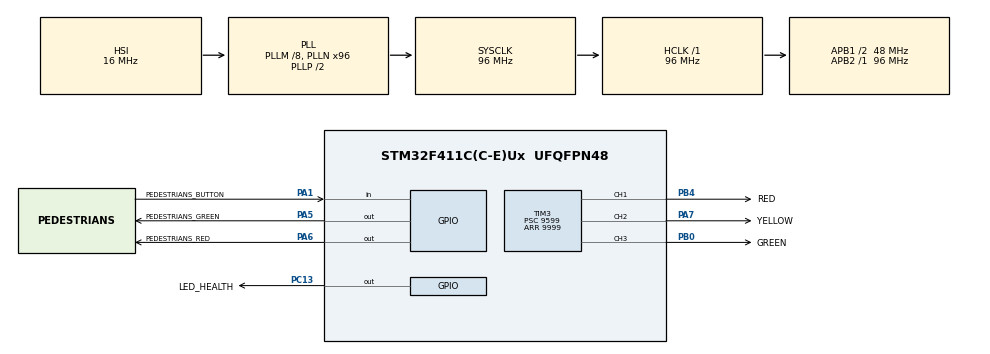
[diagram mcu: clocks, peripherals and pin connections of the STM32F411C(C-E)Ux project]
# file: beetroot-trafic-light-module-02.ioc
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Mcu.Family=STM32F4
Mcu.Name=STM32F411C(C-E)Ux
Mcu.Package=UFQFPN48
NVIC.PriorityGroup=NVIC_PRIORITYGROUP_4
NVIC.TIM2_IRQn=true\:0\:0\:false\:false\:true\:true\:true\:true
PA1.GPIO_Label=PEDESTRIANS_BUTTON
PA1.GPIO_PuPd=GPIO_PULLUP
PA1.Signal=GPIO_Input
PA5.GPIO_Label=PEDESTRIANS_GREEN
PA5.Signal=GPIO_Output
PA6.GPIO_Label=PEDESTRIANS_RED
PA6.Signal=GPIO_Output
PA7.GPIO_Label=YELLOW
PA7.Signal=S_TIM3_CH2
PB0.GPIO_Label=GREEN
PB0.Signal=S_TIM3_CH3
PB4.GPIO_Label=RED
PB4.Signal=S_TIM3_CH1
PC13-ANTI_TAMP.GPIO_Label=LED_HEALTH
PC13-ANTI_TAMP.PinState=GPIO_PIN_SET
PC13-ANTI_TAMP.Signal=GPIO_Output
PH0\ -\ OSC_IN.Mode=HSE-External-Oscillator
PH0\ -\ OSC_IN.Signal=RCC_OSC_IN
PH1\ -\ OSC_OUT.Mode=HSE-External-Oscillator
PH1\ -\ OSC_OUT.Signal=RCC_OSC_OUT
ProjectManager.HeapSize=0x200
ProjectManager.StackSize=0x400
ProjectManager.TargetToolchain=CMake
RCC.48MHZClocksFreq_Value=48000000
RCC.AHBFreq_Value=96000000
RCC.APB1CLKDivider=RCC_HCLK_DIV2
RCC.APB1Freq_Value=48000000
RCC.APB1TimFreq_Value=96000000
RCC.APB2Freq_Value=96000000
RCC.APB2TimFreq_Value=96000000
RCC.CortexFreq_Value=96000000
RCC.HCLKFreq_Value=96000000
RCC.HSE_VALUE=25000000
RCC.HSI_VALUE=16000000
RCC.PLLM=8
RCC.PLLN=96
RCC.SYSCLKFreq_VALUE=96000000
RCC.SYSCLKSource=RCC_SYSCLKSOURCE_PLLCLK
RCC.VCOOutputFreq_Value=192000000
SH.S_TIM3_CH1.0=TIM3_CH1,PWM Generation1 CH1
SH.S_TIM3_CH2.0=TIM3_CH2,PWM Generation2 CH2
SH.S_TIM3_CH3.0=TIM3_CH3,PWM Generation3 CH3
TIM2.Period=349999
TIM2.Prescaler=9599
TIM3.Channel-PWM\ Generation1\ CH1=TIM_CHANNEL_1
TIM3.Channel-PWM\ Generation2\ CH2=TIM_CHANNEL_2
TIM3.Channel-PWM\ Generation3\ CH3=TIM_CHANNEL_3
TIM3.OC1Preload_PWM=DISABLE
TIM3.OC2Preload_PWM=DISABLE
TIM3.OC3Preload_PWM=DISABLE
TIM3.Period=9999
TIM3.Prescaler=9599
VP_TIM2_VS_ClockSourceINT.Mode=Internal
board=custom

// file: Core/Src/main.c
/* USER CODE BEGIN Header */
/**
  ******************************************************************************
  * @file           : main.c
  * @brief          : Main program body
  ******************************************************************************
  * @attention
  *
  * Copyright (c) 2026 STMicroelectronics.
  * All rights reserved.
  *
  * This software is licensed under terms that can be found in the LICENSE file
  * in the root directory of this software component.
  * If no LICENSE file comes with this software, it is provided AS-IS.
  *
  ******************************************************************************
  */
/* USER CODE END Header */
#include "main.h"

/* USER CODE BEGIN Includes */
#include "traffic_light_app.h"
#include "components/health_check.h"
/* USER CODE END Includes */

TIM_HandleTypeDef htim2;
TIM_HandleTypeDef htim3;

void SystemClock_Config(void);
static void MX_GPIO_Init(void);
static void MX_TIM2_Init(void);
static void MX_TIM3_Init(void);

int main(void)
{

  /* MCU Configuration--------------------------------------------------------*/

  /* Reset of all peripherals, Initializes the Flash interface and the Systick. */
  HAL_Init();

  /* Configure the system clock */
  SystemClock_Config();

  /* Initialize all configured peripherals */
  MX_GPIO_Init();
  MX_TIM2_Init();
  MX_TIM3_Init();
  /* USER CODE BEGIN 2 */
  trafic_light_app_start(&htim2, &htim3);
  /* USER CODE END 2 */

  /* Infinite loop */
  while (1)
  {

    /* USER CODE BEGIN 3 */
    trafic_light_app_update();
    health_check_update();
  }
  /* USER CODE END 3 */
}

void SystemClock_Config(void)
{
  RCC_OscInitTypeDef RCC_OscInitStruct = {0};
  RCC_ClkInitTypeDef RCC_ClkInitStruct = {0};

  /** Configure the main internal regulator output voltage
  */
  __HAL_RCC_PWR_CLK_ENABLE();
  __HAL_PWR_VOLTAGESCALING_CONFIG(PWR_REGULATOR_VOLTAGE_SCALE1);

  /** Initializes the RCC Oscillators according to the specified parameters
  * in the RCC_OscInitTypeDef structure.
  */
  RCC_OscInitStruct.OscillatorType = RCC_OSCILLATORTYPE_HSI;
  RCC_OscInitStruct.HSIState = RCC_HSI_ON;
  RCC_OscInitStruct.HSICalibrationValue = RCC_HSICALIBRATION_DEFAULT;
  RCC_OscInitStruct.PLL.PLLState = RCC_PLL_ON;
  RCC_OscInitStruct.PLL.PLLSource = RCC_PLLSOURCE_HSI;
  RCC_OscInitStruct.PLL.PLLM = 8;
  RCC_OscInitStruct.PLL.PLLN = 96;
  RCC_OscInitStruct.PLL.PLLP = RCC_PLLP_DIV2;
  RCC_OscInitStruct.PLL.PLLQ = 4;
  if (HAL_RCC_OscConfig(&RCC_OscInitStruct) != HAL_OK)
  {
    Error_Handler();
  }

  /** Initializes the CPU, AHB and APB buses clocks
  */
  RCC_ClkInitStruct.ClockType = RCC_CLOCKTYPE_HCLK|RCC_CLOCKTYPE_SYSCLK
                              |RCC_CLOCKTYPE_PCLK1|RCC_CLOCKTYPE_PCLK2;
  RCC_ClkInitStruct.SYSCLKSource = RCC_SYSCLKSOURCE_PLLCLK;
  RCC_ClkInitStruct.AHBCLKDivider = RCC_SYSCLK_DIV1;
  RCC_ClkInitStruct.APB1CLKDivider = RCC_HCLK_DIV2;
  RCC_ClkInitStruct.APB2CLKDivider = RCC_HCLK_DIV1;

  if (HAL_RCC_ClockConfig(&RCC_ClkInitStruct, FLASH_LATENCY_3) != HAL_OK)
  {
    Error_Handler();
  }
}

static void MX_TIM2_Init(void)
{

  TIM_ClockConfigTypeDef sClockSourceConfig = {0};
  TIM_MasterConfigTypeDef sMasterConfig = {0};

  htim2.Instance = TIM2;
  htim2.Init.Prescaler = 9599;
  htim2.Init.CounterMode = TIM_COUNTERMODE_UP;
  htim2.Init.Period = 349999;
  htim2.Init.ClockDivision = TIM_CLOCKDIVISION_DIV1;
  htim2.Init.AutoReloadPreload = TIM_AUTORELOAD_PRELOAD_DISABLE;
  if (HAL_TIM_Base_Init(&htim2) != HAL_OK)
  {
    Error_Handler();
  }
  sClockSourceConfig.ClockSource = TIM_CLOCKSOURCE_INTERNAL;
  if (HAL_TIM_ConfigClockSource(&htim2, &sClockSourceConfig) != HAL_OK)
  {
    Error_Handler();
  }
  sMasterConfig.MasterOutputTrigger = TIM_TRGO_RESET;
  sMasterConfig.MasterSlaveMode = TIM_MASTERSLAVEMODE_DISABLE;
  if (HAL_TIMEx_MasterConfigSynchronization(&htim2, &sMasterConfig) != HAL_OK)
  {
    Error_Handler();
  }

}

static void MX_TIM3_Init(void)
{

  TIM_MasterConfigTypeDef sMasterConfig = {0};
  TIM_OC_InitTypeDef sConfigOC = {0};

  htim3.Instance = TIM3;
  htim3.Init.Prescaler = 9599;
  htim3.Init.CounterMode = TIM_COUNTERMODE_UP;
  htim3.Init.Period = 9999;
  htim3.Init.ClockDivision = TIM_CLOCKDIVISION_DIV1;
  htim3.Init.AutoReloadPreload = TIM_AUTORELOAD_PRELOAD_DISABLE;
  if (HAL_TIM_PWM_Init(&htim3) != HAL_OK)
  {
    Error_Handler();
  }
  sMasterConfig.MasterOutputTrigger = TIM_TRGO_RESET;
  sMasterConfig.MasterSlaveMode = TIM_MASTERSLAVEMODE_DISABLE;
  if (HAL_TIMEx_MasterConfigSynchronization(&htim3, &sMasterConfig) != HAL_OK)
  {
    Error_Handler();
  }
  sConfigOC.OCMode = TIM_OCMODE_PWM1;
  sConfigOC.Pulse = 0;
  sConfigOC.OCPolarity = TIM_OCPOLARITY_HIGH;
  sConfigOC.OCFastMode = TIM_OCFAST_DISABLE;
  if (HAL_TIM_PWM_ConfigChannel(&htim3, &sConfigOC, TIM_CHANNEL_1) != HAL_OK)
  {
    Error_Handler();
  }
  __HAL_TIM_DISABLE_OCxPRELOAD(&htim3, TIM_CHANNEL_1);
  if (HAL_TIM_PWM_ConfigChannel(&htim3, &sConfigOC, TIM_CHANNEL_2) != HAL_OK)
  {
    Error_Handler();
  }
  __HAL_TIM_DISABLE_OCxPRELOAD(&htim3, TIM_CHANNEL_2);
  if (HAL_TIM_PWM_ConfigChannel(&htim3, &sConfigOC, TIM_CHANNEL_3) != HAL_OK)
  {
    Error_Handler();
  }
  __HAL_TIM_DISABLE_OCxPRELOAD(&htim3, TIM_CHANNEL_3);
  HAL_TIM_MspPostInit(&htim3);

}

static void MX_GPIO_Init(void)
{
  GPIO_InitTypeDef GPIO_InitStruct = {0};

  /* GPIO Ports Clock Enable */
  __HAL_RCC_GPIOC_CLK_ENABLE();
  __HAL_RCC_GPIOH_CLK_ENABLE();
  __HAL_RCC_GPIOA_CLK_ENABLE();
  __HAL_RCC_GPIOB_CLK_ENABLE();

  /*Configure GPIO pin Output Level */
  HAL_GPIO_WritePin(LED_HEALTH_GPIO_Port, LED_HEALTH_Pin, GPIO_PIN_SET);

  /*Configure GPIO pin Output Level */
  HAL_GPIO_WritePin(GPIOA, PEDESTRIANS_GREEN_Pin|PEDESTRIANS_RED_Pin, GPIO_PIN_RESET);

  /*Configure GPIO pin : LED_HEALTH_Pin */
  GPIO_InitStruct.Pin = LED_HEALTH_Pin;
  GPIO_InitStruct.Mode = GPIO_MODE_OUTPUT_PP;
  GPIO_InitStruct.Pull = GPIO_NOPULL;
  GPIO_InitStruct.Speed = GPIO_SPEED_FREQ_LOW;
  HAL_GPIO_Init(LED_HEALTH_GPIO_Port, &GPIO_InitStruct);

  /*Configure GPIO pin : PEDESTRIANS_BUTTON_Pin */
  GPIO_InitStruct.Pin = PEDESTRIANS_BUTTON_Pin;
  GPIO_InitStruct.Mode = GPIO_MODE_INPUT;
  GPIO_InitStruct.Pull = GPIO_PULLUP;
  HAL_GPIO_Init(PEDESTRIANS_BUTTON_GPIO_Port, &GPIO_InitStruct);

  /*Configure GPIO pins : PEDESTRIANS_GREEN_Pin PEDESTRIANS_RED_Pin */
  GPIO_InitStruct.Pin = PEDESTRIANS_GREEN_Pin|PEDESTRIANS_RED_Pin;
  GPIO_InitStruct.Mode = GPIO_MODE_OUTPUT_PP;
  GPIO_InitStruct.Pull = GPIO_NOPULL;
  GPIO_InitStruct.Speed = GPIO_SPEED_FREQ_LOW;
  HAL_GPIO_Init(GPIOA, &GPIO_InitStruct);

}

void Error_Handler(void)
{
  __disable_irq();
  while (1)
  {
  }
}
